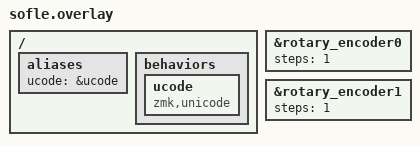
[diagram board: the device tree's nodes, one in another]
/ {
    aliases {
        ucode = &ucode;
    };

    behaviors {
        ucode: ucode {
            compatible = "zmk,unicode";
            #binding-cells = <1>;
        };
    };
};

&rotary_encoder0 {
    steps = <1>;
};

&rotary_encoder1 {
    steps = <1>;
};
